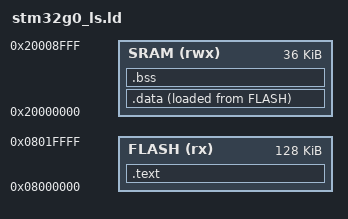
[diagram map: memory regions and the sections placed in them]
ENTRY(reset_handler)

MEMORY {
    FLASH(rx) : ORIGIN = 0x08000000, LENGTH = 128K
    SRAM(rwx) : ORIGIN = 0x20000000, LENGTH = 36K
}

_endstack = ORIGIN(SRAM) + LENGTH(SRAM);

/* As per CubeIDE autogenerated file because could not find value in datasheet */
minHeapSize = 0x200; 
minStackSize = 0x400;

SECTIONS {

    .text : {
        . = ALIGN(4); /* Aligns the start of the section to a 4-byte boundary */
        
        *(.isr_vector_tbl) /* Pulls in all sections named .isr_vector_tbl from input files into current location in .text section */

        *(.text) /* Pulls in all sections named .text from input files into current location in .text section */

        *(.rodata) /* Pulls in all sections named .rodata from input files into current location in .text section */

        . = ALIGN(4); /* Aligns the end of the section to a 4-byte boundary */

        _endtext = .; /* Symbol marking end of .text seciton. Used as a pointer in startup file. */
    } > FLASH   /* Specifies section to be placed in FLASH memory as defined earlier */

    .data : {
        . = ALIGN(4);

        _startdata = .; /* Symbol to start of .data section. Used as pointer */

        *(.data) /* Pulls in all sections named .data from input files */

        . = ALIGN(4);

        _enddata = .;
    } > SRAM AT> FLASH /* In form "> (VMA) AT> (LMA)". Initial values in FLASH, store in SRAM at runtime. */

    .bss : {
        . = ALIGN(4);

        _startbss = .;

        *(.bss)

        . = ALIGN(4);

        _endbss = .;

    } > SRAM

}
